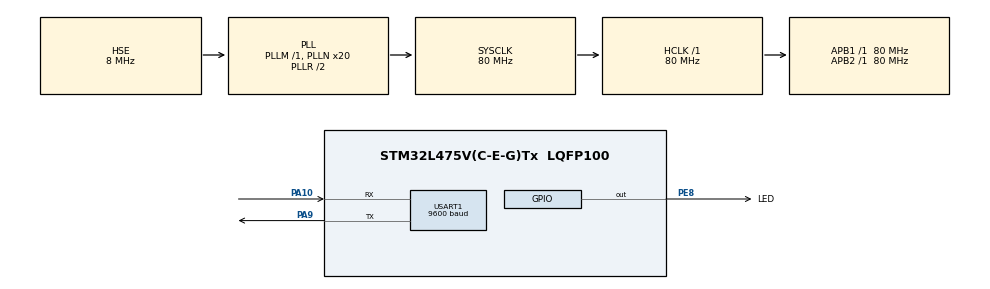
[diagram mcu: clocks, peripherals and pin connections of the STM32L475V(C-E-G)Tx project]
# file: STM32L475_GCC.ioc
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Dma.Request0=USART1_RX
Dma.Request1=USART1_TX
Dma.USART1_RX.0.Direction=DMA_PERIPH_TO_MEMORY
Dma.USART1_RX.0.Instance=DMA1_Channel5
Dma.USART1_RX.0.MemDataAlignment=DMA_MDATAALIGN_BYTE
Dma.USART1_RX.0.MemInc=DMA_MINC_ENABLE
Dma.USART1_RX.0.Mode=DMA_CIRCULAR
Dma.USART1_RX.0.PeriphDataAlignment=DMA_PDATAALIGN_BYTE
Dma.USART1_RX.0.PeriphInc=DMA_PINC_DISABLE
Dma.USART1_RX.0.Priority=DMA_PRIORITY_LOW
Dma.USART1_TX.1.Direction=DMA_MEMORY_TO_PERIPH
Dma.USART1_TX.1.Instance=DMA1_Channel4
Dma.USART1_TX.1.MemDataAlignment=DMA_MDATAALIGN_BYTE
Dma.USART1_TX.1.MemInc=DMA_MINC_ENABLE
Dma.USART1_TX.1.Mode=DMA_NORMAL
Dma.USART1_TX.1.PeriphDataAlignment=DMA_PDATAALIGN_BYTE
Dma.USART1_TX.1.PeriphInc=DMA_PINC_DISABLE
Dma.USART1_TX.1.Priority=DMA_PRIORITY_LOW
Mcu.Family=STM32L4
Mcu.Name=STM32L475V(C-E-G)Tx
Mcu.Package=LQFP100
NVIC.DMA1_Channel4_IRQn=true\:0\:0\:false\:false\:true\:false\:true\:true
NVIC.DMA1_Channel5_IRQn=true\:0\:0\:false\:false\:true\:false\:true\:true
NVIC.PriorityGroup=NVIC_PRIORITYGROUP_4
NVIC.USART1_IRQn=true\:4\:0\:true\:false\:true\:true\:true\:true
PA10.Mode=Asynchronous
PA10.Signal=USART1_RX
PA13\ (JTMS-SWDIO).Mode=Serial_Wire
PA13\ (JTMS-SWDIO).Signal=SYS_JTMS-SWDIO
PA14\ (JTCK-SWCLK).Mode=Serial_Wire
PA14\ (JTCK-SWCLK).Signal=SYS_JTCK-SWCLK
PA9.Mode=Asynchronous
PA9.Signal=USART1_TX
PE8.GPIO_Label=LED
PE8.Signal=GPIO_Output
PH0-OSC_IN\ (PH0).Mode=HSE-External-Oscillator
PH0-OSC_IN\ (PH0).Signal=RCC_OSC_IN
PH1-OSC_OUT\ (PH1).Mode=HSE-External-Oscillator
PH1-OSC_OUT\ (PH1).Signal=RCC_OSC_OUT
ProjectManager.HeapSize=0x200
ProjectManager.StackSize=0x400
ProjectManager.TargetToolchain=Makefile
RCC.ADCFreq_Value=32000000
RCC.AHBFreq_Value=80000000
RCC.APB1Freq_Value=80000000
RCC.APB1TimFreq_Value=80000000
RCC.APB2Freq_Value=80000000
RCC.APB2TimFreq_Value=80000000
RCC.CortexFreq_Value=80000000
RCC.HCLKFreq_Value=80000000
RCC.HSE_VALUE=8000000
RCC.HSI_VALUE=16000000
RCC.LSE_VALUE=32768
RCC.MSI_VALUE=4000000
RCC.PLLN=20
RCC.PLLSourceVirtual=RCC_PLLSOURCE_HSE
RCC.SYSCLKFreq_VALUE=80000000
RCC.SYSCLKSource=RCC_SYSCLKSOURCE_PLLCLK
RCC.USBFreq_Value=32000000
RCC.VCOOutputFreq_Value=160000000
USART1.BaudRate=9600
USART1.VirtualMode-Asynchronous=VM_ASYNC
board=custom

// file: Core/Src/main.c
/* USER CODE BEGIN Header */
/**
  ******************************************************************************
  * @file           : main.c
  * @brief          : Main program body
  ******************************************************************************
  * @attention
  *
  * Copyright (c) 2022 STMicroelectronics.
  * All rights reserved.
  *
  * This software is licensed under terms that can be found in the LICENSE file
  * in the root directory of this software component.
  * If no LICENSE file comes with this software, it is provided AS-IS.
  *
  ******************************************************************************
  */
/* USER CODE END Header */
#include "main.h"
#include "dma.h"
#include "usart.h"
#include "gpio.h"

void SystemClock_Config(void);

/* USER CODE BEGIN 0 */
  USART_TYPE  Usart_RX;
/* USER CODE END 0 */

int main(void)
{

  /* MCU Configuration--------------------------------------------------------*/

  /* Reset of all peripherals, Initializes the Flash interface and the Systick. */
  HAL_Init();

  /* Configure the system clock */
  SystemClock_Config();

  /* Initialize all configured peripherals */
  MX_GPIO_Init();
  MX_DMA_Init();
  MX_USART1_UART_Init();
  /* USER CODE BEGIN 2 */
  	Usart_RX.s=0;Usart_RX.sv=0;
	 __HAL_UART_CLEAR_IDLEFLAG(&huart1);
  /* 使能串口空闲中断 */
  __HAL_UART_ENABLE_IT(&huart1, UART_IT_IDLE);
  /* 配置串口 DMA接收 */
	HAL_UART_Receive_DMA(&huart1, Usart_RX.DMA_pData, USART_MAX_LEN);
  /* USER CODE END 2 */

  /* Infinite loop */
  /* USER CODE BEGIN WHILE */
  while (1)
  {
    UART_RxProtocol();
    /* USER CODE END WHILE */

  }
}

void SystemClock_Config(void)
{
  RCC_OscInitTypeDef RCC_OscInitStruct = {0};
  RCC_ClkInitTypeDef RCC_ClkInitStruct = {0};

  /** Configure the main internal regulator output voltage
  */
  if (HAL_PWREx_ControlVoltageScaling(PWR_REGULATOR_VOLTAGE_SCALE1) != HAL_OK)
  {
    Error_Handler();
  }

  /** Initializes the RCC Oscillators according to the specified parameters
  * in the RCC_OscInitTypeDef structure.
  */
  RCC_OscInitStruct.OscillatorType = RCC_OSCILLATORTYPE_HSE;
  RCC_OscInitStruct.HSEState = RCC_HSE_ON;
  RCC_OscInitStruct.PLL.PLLState = RCC_PLL_ON;
  RCC_OscInitStruct.PLL.PLLSource = RCC_PLLSOURCE_HSE;
  RCC_OscInitStruct.PLL.PLLM = 1;
  RCC_OscInitStruct.PLL.PLLN = 20;
  RCC_OscInitStruct.PLL.PLLP = RCC_PLLP_DIV7;
  RCC_OscInitStruct.PLL.PLLQ = RCC_PLLQ_DIV2;
  RCC_OscInitStruct.PLL.PLLR = RCC_PLLR_DIV2;
  if (HAL_RCC_OscConfig(&RCC_OscInitStruct) != HAL_OK)
  {
    Error_Handler();
  }

  /** Initializes the CPU, AHB and APB buses clocks
  */
  RCC_ClkInitStruct.ClockType = RCC_CLOCKTYPE_HCLK|RCC_CLOCKTYPE_SYSCLK
                              |RCC_CLOCKTYPE_PCLK1|RCC_CLOCKTYPE_PCLK2;
  RCC_ClkInitStruct.SYSCLKSource = RCC_SYSCLKSOURCE_PLLCLK;
  RCC_ClkInitStruct.AHBCLKDivider = RCC_SYSCLK_DIV1;
  RCC_ClkInitStruct.APB1CLKDivider = RCC_HCLK_DIV1;
  RCC_ClkInitStruct.APB2CLKDivider = RCC_HCLK_DIV1;

  if (HAL_RCC_ClockConfig(&RCC_ClkInitStruct, FLASH_LATENCY_4) != HAL_OK)
  {
    Error_Handler();
  }
}

/* USER CODE BEGIN 4 */

/**
  * @brief  串口空闲处理函数
  */
void UsartReceive_IDLE(UART_HandleTypeDef *huart)
{
    if((__HAL_UART_GET_FLAG(huart,UART_FLAG_IDLE) != RESET))
    {
        __HAL_UART_CLEAR_IDLEFLAG(huart); /* 清除串口空闲中断标志 */
				Usart_RX.s=USART_MAX_LEN - __HAL_DMA_GET_COUNTER(huart->hdmarx);
    }
}

/**
  * @brief  串口接收回调函数
  */
void HAL_UART_RxCpltCallback(UART_HandleTypeDef *huart)
{
	Usart_RX.s=0;//接收数据到缓冲区的尾部时从0开始
}

/**
  * @brief  更新指针保证及时处理数据，采用乒乓Buffer想法
  */
void HAL_UART_RxHalfCpltCallback(UART_HandleTypeDef *huart)
{
	Usart_RX.s=USART_MAX_LEN/2;//接收数据到缓冲区的一半时更新
}

/**
  * @brief  串口接收处理主函数，放main里运行
  */
void UART_RxProtocol(void)
{
	uint8_t len;
	if(Usart_RX.s!=Usart_RX.sv) //但指针不等时说明有数据待处理
  {
    /* len为待处理数据的长度 */
    // len=(Usart_RX.s>Usart_RX.sv)?(Usart_RX.s-Usart_RX.sv):(USART_MAX_LEN+Usart_RX.s-Usart_RX.sv);
    /*
    处理的主函数，可以做数据的搬运，也可以直接处理数据
    处理数据后需更新Usart_RX.sv，可以一个一个字节处理，也可以一次性处理len长度
    注：处理速度和发送速度必须大于接收速度，否则该方案完全不成立！
     */
    HAL_UART_Transmit(&huart1,Usart_RX.DMA_pData+Usart_RX.sv,1,0xff);//echo仅做演示，实际不应该使用
    Usart_RX.sv++;
    if(Usart_RX.sv>=USART_MAX_LEN)
    Usart_RX.sv=0;
  }
}
/* USER CODE END 4 */

void Error_Handler(void)
{
  __disable_irq();
  while (1)
  {
  }
}
